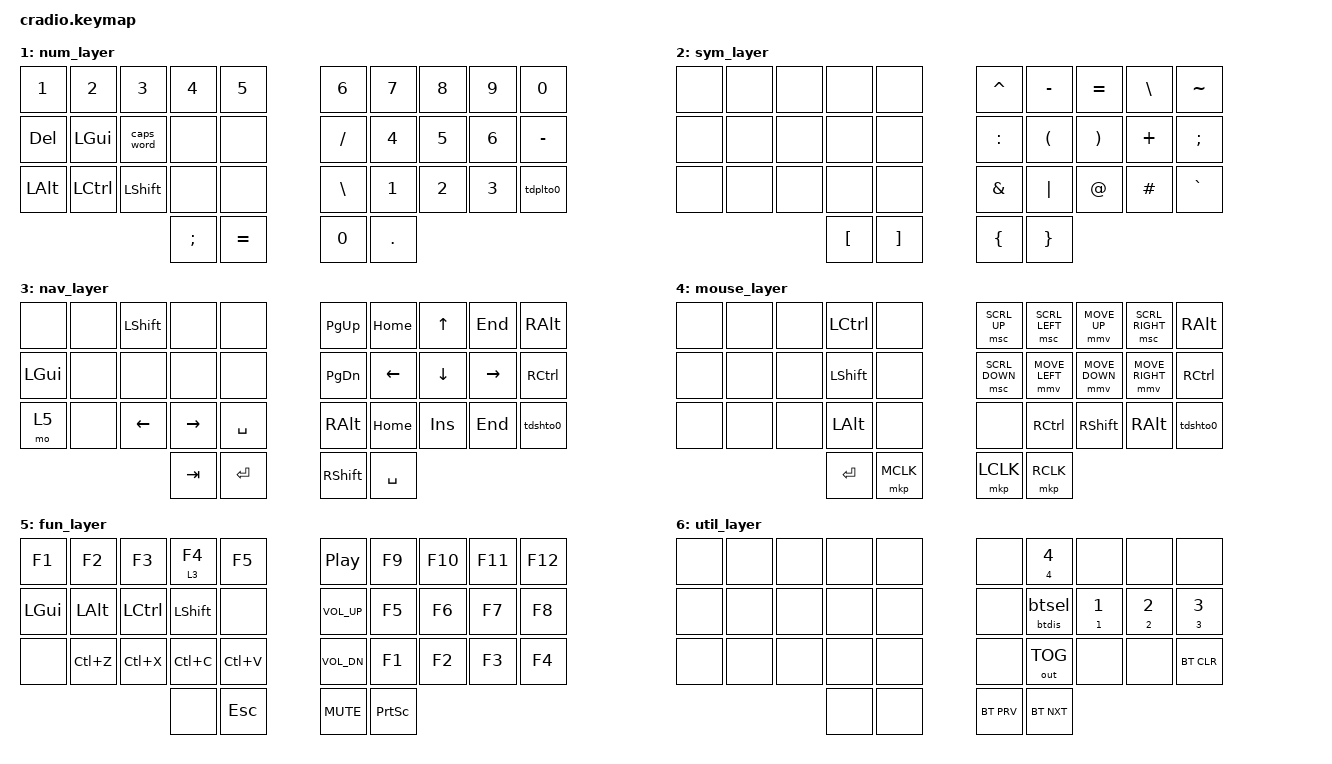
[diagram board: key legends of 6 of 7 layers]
// Copyright (c) 2022 The ZMK Contributors
// SPDX-License-Identifier: MIT

#include <behaviors.dtsi>
#include <dt-bindings/zmk/keys.h>
#include <dt-bindings/zmk/bt.h>
#include <dt-bindings/zmk/outputs.h>
#include <dt-bindings/zmk/pointing.h>

// Home row mods macro
#define HRML(k1,k2,k3,k4) &ht LGUI k1  &ht LALT k2  &ht LCTRL k3  &ht LSHFT k4
#define HRMR(k1,k2,k3,k4) &ht RSHFT k1  &ht RCTRL k2  &ht RALT k3  &ht RGUI k4

/ {
    behaviors {
        ht: hold_tap {
            compatible = "zmk,behavior-hold-tap";
            #binding-cells = <2>;
            flavor = "tap-preferred";
            tapping-term-ms = <200>;
            quick-tap-ms = <120>;
            require-prior-idle-ms = <100>;
            bindings = <&kp>, <&kp>;
        };
        btht: bluetooth_hold_tap {
            compatible = "zmk,behavior-hold-tap";
            #binding-cells = <2>;
            flavor = "tap-preferred";
            tapping-term-ms = <2000>;
            require-prior-idle-ms = <100>;
            bindings = <&btdis>, <&btsel>;
        };
        tdshto0: tapdance_shift_tolayer0 {
            compatible = "zmk,behavior-tap-dance";
            display-name = "TD Shift/L0";
            #binding-cells = <0>;
            bindings = <&kp LEFT_SHIFT>, <&to 0>;
        };
        tdplto0: tapdance_plus_tolayer0 {
            compatible = "zmk,behavior-tap-dance";
            display-name = "TD +/L0";
            #binding-cells = <0>;
            bindings = <&kp EQUAL>, <&to 0>;
        };
    };
    macros {
        btsel: bluetooth_select {
            compatible = "zmk,behavior-macro-one-param";
            #binding-cells = <1>;
            bindings
                = <&macro_param_1to2>
                , <&macro_tap &bt BT_SEL MACRO_PLACEHOLDER>
                , <&macro_tap &out OUT_BLE>
                ;
        };
        btdis: bluetooth_disconnect {
            compatible = "zmk,behavior-macro-one-param";
            #binding-cells = <1>;
            bindings
                = <&macro_param_1to2>
                , <&macro_tap &bt BT_DISC MACRO_PLACEHOLDER>
                ;
        };
    };
    combos {
        compatible = "zmk,combos";
        combo_minimize {
            timeout-ms = <30>;
            key-positions = <0 4>;
            bindings = <&kp LG(DOWN)>;
        };
        combo_esc {
            timeout-ms = <30>;
            key-positions = <0 1>;
            bindings = <&kp ESC>;
        };
        combo_caps_word {
            timeout-ms = <30>;
            key-positions = <2 3>;
            bindings = <&caps_word>;
        };
        combo_del {
            timeout-ms = <30>;
            key-positions = <6 7>;
            bindings = <&kp DEL>;
        };
        combo_kapp {
            timeout-ms = <30>;
            key-positions = <0 1>;
            bindings = <&kp K_APP>;
        };
        combo_navlock_on {
            timeout-ms = <40>;
            key-positions = <25 27>;
            layers = <0 1 4 >;
            bindings = <&to 3>;
        };
        combo_navlock_off {
            timeout-ms = <40>;
            key-positions = <25 27>;
            layers = <3>;
            bindings = <&to 0>;
        };
        combo_numlock_on {
            timeout-ms = <40>;
            key-positions = <26 28>;
            layers = <0 3 4>;
            bindings = <&to 1>;
        };
        combo_numlock_off {
            timeout-ms = <40>;
            key-positions = <26 28>;
            layers = <1>;
            bindings = <&to 0>;
        };
        combo_mouselock_on {
            timeout-ms = <40>;
            key-positions = <27 29>;
            layers = <0 1 3>;
            bindings = <&to 4>;
        };
        combo_mouselock_off {
            timeout-ms = <40>;
            key-positions = <27 29>;
            layers = <4>;
            bindings = <&to 0>;
        };
    };

    conditional_layers {
        compatible = "zmk,conditional-layers";
        util_layer {
            if-layers = <3 5>;
            then-layer = <6>;
        };
    };

    keymap {
        compatible = "zmk,keymap";
        default_layer {
            bindings = <
        //╭──────────┬──────────┬──────────┬──────────┬──────────╮   ╭──────────┬──────────┬──────────┬──────────┬──────────╮
        //│  Q       │  W       │  F       │  P       │  B       │   │  J       │  L       │  U       │  Y       │ ' "      │
            &kp Q      &kp W      &lt 4 F    &lt 3 P    &kp B          &kp J      &lt 3 L    &lt 4 U    &kp Y      &kp SQT
        //├──────────┼──────────┼──────────┼──────────┼──────────┤   ├──────────┼──────────┼──────────┼──────────┼──────────┤
        //│  A       │  R       │  S       │  T       │  G       │   │  M       │  N       │  E       │  I       │ O        │
            HRML(A,        R,         S,         T)     &kp G          &kp M      HRMR(N,        E,         I,        O)
        //├──────────┼──────────┼──────────┼──────────┼──────────┤   ├──────────┼──────────┼──────────┼──────────┼──────────┤
        //│  Z       │  X       │  C       │  D       │  V       │   │  K       │  H       │ , <      │ . >      │ / ?      │
            &lt 5 Z    &kp X      &lt 2 C    &lt 1 D    &kp V          &kp K      &lt 1 H  &lt 2 COMMA  &kp DOT   &lt 5 FSLH
        //╰──────────┴──────────┴──────────┼──────────┼──────────┤   ├──────────┼──────────┼──────────┴──────────┴──────────╯
                                            &kp TAB     &kp ENTER     &kp SPACE  &kp BSPC
        //                                 ╰──────────┴──────────╯   ╰──────────┴──────────╯
            >;
        };

        num_layer {
            bindings = <
        //╭──────────┬──────────┬──────────┬──────────┬──────────╮   ╭──────────┬──────────┬──────────┬──────────┬──────────╮
        //│ 1 !      │ 2 @      │ 3 #      │ 4 $      │ 5 %      │   │ 6 ^      │ 7 &      │ 8 *      │ 9 (      │  0 )     │
            &kp N1     &kp N2     &kp N3     &kp N4     &kp N5         &kp N6     &kp N7     &kp N8     &kp N9     &kp N0
        //├──────────┼──────────┼──────────┼──────────┼──────────┤   ├──────────┼──────────┼──────────┼──────────┼──────────┤
        //│ DELETE   │ WINDERS  │ CAPS     │          │          │   │ / ?      │ 4 $      │ 5 %      │ 6 ^      │  -       │
            &kp DEL    &kp LGUI  &caps_word   &none      &none         &kp FSLH   &kp N4     &kp N5     &kp N6     &kp MINUS
        //├──────────┼──────────┼──────────┼──────────┼──────────┤   ├──────────┼──────────┼──────────┼──────────┼──────────┤
        //│          │          │          │This Layer│          │   │ \ |      │ 1 !      │ 2 @      │ 3 #      │  +       │
           &kp LALT   &kp LCTRL  &kp LSHFT   &none      &none         &kp BSLH   &kp N1     &kp N2     &kp N3     &tdplto0
        //╰──────────┴──────────┴──────────┼──────────┼──────────┤   ├──────────┼──────────┼──────────┴──────────┴──────────╯
                                             &kp SEMI   &kp EQUAL       &kp N0     &kp DOT
        //                                 ╰──────────┴──────────╯   ╰──────────┴──────────╯
            >;
        };

        sym_layer {
            bindings = <
        //╭──────────┬──────────┬──────────┬──────────┬──────────╮   ╭──────────┬──────────┬──────────┬──────────┬──────────╮
        //│          │          │          │          │          │   │  ^       │  -       │  =       │  \       │  ~       │
            &none      &none      &none     &none       &none          &kp CARET  &kp MINUS &kp EQUAL   &kp BSLH   &kp TILDE
        //├──────────┼──────────┼──────────┼──────────┼──────────┤   ├──────────┼──────────┼──────────┼──────────┼──────────┤
        //│          │          │          │          │          │   │  :       │  (       │  )       │  +       │  ;       │
            &none      &none     &none      &none       &none          &kp COLON  &kp LPAR   &kp RPAR   &kp PLUS   &kp SEMI
        //├──────────┼──────────┼──────────┼──────────┼──────────┤   ├──────────┼──────────┼──────────┼──────────┼──────────┤
        //│          │          │This Layer│          │          │   │  &       │  |       │  @       │  #       │  `       │ Delete collided with num_layer LSHIFT
            &none      &none      &none      &none      &none         &kp AMPS   &kp PIPE   &kp AT     &kp HASH   &kp GRAVE
        //╰──────────┴──────────┴──────────┼──────────┼──────────┤   ├──────────┼──────────┼──────────┴──────────┴──────────╯
                                             &kp LBKT    &kp RBKT      &kp LBRC   &kp RBRC
        //                                 ╰──────────┴──────────╯   ╰──────────┴──────────╯
            >;
        };

        nav_layer {
            bindings = <
        //╭──────────┬──────────┬──────────┬──────────┬──────────╮   ╭──────────┬──────────┬──────────┬──────────┬──────────╮
        //│          │          │ Shift    │This Layer│          │   │ Page Up  │ Home     │    UP    │ End      │ Alt      │
           &none      &none       &kp LSHFT  &none      &none         &kp PG_UP   &kp HOME    &kp UP    &kp END    &kp RALT
        //├──────────┼──────────┼──────────┼──────────┼──────────┤   ├──────────┼──────────┼──────────┼──────────┼──────────┤
        //│ WINDOZE  │          │          │          │          │   │ Page Down│  LEFT    │   DOWN   │  RIGHT   │ Ctrl     │
           &kp LGUI   &none       &none       &none     &none         &kp PG_DN   &kp LEFT   &kp DOWN   &kp RIGHT  &kp RCTRL 
        //├──────────┼──────────┼──────────┼──────────┼──────────┤   ├──────────┼──────────┼──────────┼──────────┼──────────┤
        //│          │          │          │          │          │   │ Alt      │ Home     │ Insert   │ End      │SHIFT + L0│
           &mo 5      &none       &kp LEFT   &kp RIGHT  &kp SPACE      &kp RALT   &kp HOME   &kp INS    &kp END    &tdshto0
        //╰──────────┴──────────┴──────────┼──────────┼──────────┤   ├──────────┼──────────┼──────────┴──────────┴──────────╯
                                            &kp TAB     &kp ENTER     &kp RSHFT  &kp SPACE
        //                                 ╰──────────┴──────────╯   ╰──────────┴──────────╯
            >;
        };

        mouse_layer {
            bindings = <
        //╭──────────┬──────────┬──────────┬──────────┬──────────╮   ╭───────────────┬───────────────┬───────────────┬───────────────┬───────────────╮
        //│          │          │This Layer│ Control  │          │   │               │               │               │               │               │
           &none      &none       &none      &kp LCTRL  &none         &msc SCRL_UP     &msc SCRL_LEFT  &mmv MOVE_UP   &msc SCRL_RIGHT  &kp RALT
        //├──────────┼──────────┼──────────┼──────────┼──────────┤   ├───────────────┼───────────────┼───────────────┼───────────────┼───────────────┤
        //│          │          │          │  Shift   │          │   │               │               │               │               │               │
           &none      &none       &none      &kp LSHFT  &none         &msc SCRL_DOWN   &mmv MOVE_LEFT  &mmv MOVE_DOWN &mmv MOVE_RIGHT  &kp RCTRL
        //├──────────┼──────────┼──────────┼──────────┼──────────┤   ├───────────────┼───────────────┼───────────────┼───────────────┼───────────────┤
        //│          │          │          │  Alt     │          │   │               │ Control       │ Shift         │  Alt          │  SHIFT + L0   │
           &none      &none       &none      &kp LALT   &none          &none           &kp RCTRL       &kp RSHFT       &kp RALT          &tdshto0
        //╰──────────┴──────────┴──────────┼──────────┼──────────┤   ├───────────────┼───────────────┼───────────────┴───────────────┴───────────────╯
                                            &kp ENTER   &mkp MCLK     &mkp LCLK        &mkp RCLK 
        //                                 ╰──────────┴──────────╯   ╰───────────────┴───────────────╯
            >;
        };

        fun_layer {
            bindings = <
        //╭──────────┬──────────┬──────────┬──────────┬──────────╮   ╭──────────┬──────────┬──────────┬──────────┬──────────╮
        //│          │          │          │          │          │   │Play/Pause│          │          │          │          │
           &kp F1      &kp F2     &kp F3     &lt 3 F4   &kp F5         &kp C_PP    &kp F9    &kp F10    &kp F11    &kp F12
        //├──────────┼──────────┼──────────┼──────────┼──────────┤   ├──────────┼──────────┼──────────┼──────────┼──────────┤
        //│          │          │          │          │          │   │ Volume + │          │          │          │          │
           &kp LGUI   &kp LALT   &kp LCTRL  &kp LSHFT   &none        &kp C_VOL_UP  &kp F5    &kp F6     &kp F7     &kp F8
        //├──────────┼──────────┼──────────┼──────────┼──────────┤   ├──────────┼──────────┼──────────┼──────────┼──────────┤
        //│This Layer│  Undo    │  Cut     │  Copy    │  Paste   │   │ Volume - │          │          │          │          │
           &none      &kp LC(Z)  &kp LC(X)  &kp LC(C)   &kp LC(V)    &kp C_VOL_DN  &kp F1    &kp F2     &kp F3     &kp F4   
        //╰──────────┴──────────┴──────────┼──────────┼──────────┤   ├──────────┼──────────┼──────────┴──────────┴──────────╯
                                              &none     &kp ESC       &kp C_MUTE  &kp PSCRN
        //                                 ╰──────────┴──────────╯   ╰──────────┴──────────╯
            >;
        };

        util_layer {
            bindings = <
        //╭──────────┬──────────┬──────────┬──────────┬──────────╮   ╭──────────┬──────────────┬──────────────┬──────────────┬──────────────╮
        //│          │          │          │This Layer│          │   │          │ Guest        │              │              │              │
           &none      &none       &none       &none     &none          &none      &btht 4 4      &none           &none         &none
        //├──────────┼──────────┼──────────┼──────────┼──────────┤   ├──────────┼──────────────┼──────────────┼──────────────┼──────────────┤
        //│          │          │          │          │          │   │          │ Big Lappy    │ Work Lappy   │ Tiny Lappy   │   Phone      │
           &none      &none       &none       &none     &none          &none      &btht 0 0      &btht 1 1      &btht 2 2      &btht 3 3
        //├──────────┼──────────┼──────────┼──────────┼──────────┤   ├──────────┼──────────────┼──────────────┼──────────────┼──────────────┤
        //│This Layer│          │          │          │          │   │          │ USB/BLE      │              │              │Clear Profile │
           &none      &none       &none       &none     &none          &none      &out OUT_TOG    &none           &none        &bt BT_CLR
        //╰──────────┴──────────┴──────────┼──────────┼──────────┤   ├──────────┼──────────────┼──────────────┴──────────────┴──────────────╯
                                              &none     &none         &bt BT_PRV &bt BT_NXT
        //                                 ╰──────────┴──────────╯   ╰──────────┴──────────╯
            >;
        };
    };
};
